# STM32F070x6 register map
File version: 1.0
Registers are 32-bit, read-write, reset 0x0 unless marked. A register's access mark holds for its fields unless they carry their own. Offsets are from the block's base; [hi:lo] are bit positions; {n}, {i} and the like mark numbered series.

## ADC
Base 0x40012708
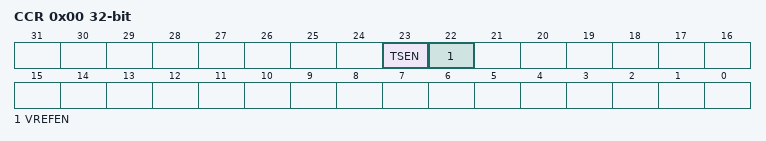
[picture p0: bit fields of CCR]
0x00 CCR — ADC common configuration register
  [23] TSEN — ADC internal path to temperature sensor enable
  [22] VREFEN — ADC internal path to VrefInt enable

## SPI1 — Serial Peripheral Interface
Base 0x40013000
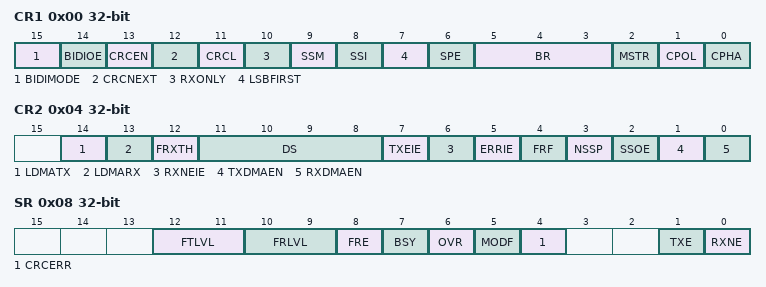
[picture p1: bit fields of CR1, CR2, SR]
0x00 CR1 — SPI Control register 1 (not used in I2S mode)
  [15] BIDIMODE — Bidirectional data mode enable
  [14] BIDIOE — Output enable in bidirectional mode
  [13] CRCEN — Hardware CRC calculation enable
  [12] CRCNEXT — Transmit CRC next
  [11] CRCL — CRC Length
    0=CRC_8BIT (8-bit CRC length); 1=CRC_16BIT (16-bit CRC length)
  [10] RXONLY — Receive only
  [9] SSM — Software slave management
  [8] SSI — Internal slave select
  [7] LSBFIRST — Frame Format
    1=LSB_FIRST (Data is transmitted/received with the LSB first); 0=MSB_FIRST (Data is transmitted/received with the MSB first)
  [6] SPE — SPI Enable
  [5:3] BR — BR[2:0] bits (Baud Rate Control)
    0=DIV2 (BaudRate control equal to fPCLK/2); 1=DIV4 (BaudRate control equal to fPCLK/4); 2=DIV8 (BaudRate control equal to fPCLK/8); 3=DIV16 (BaudRate control equal to fPCLK/16); 4=DIV32 (BaudRate control equal to fPCLK/32); 5=DIV64 (BaudRate control equal to fPCLK/64); 6=DIV128 (BaudRate control equal to fPCLK/128); 7=DIV256 (BaudRate control equal to fPCLK/256)
  [2] MSTR — Master Selection
  [1] CPOL — Clock Polarity
    0=LOW (Clock to 0 when idle); 1=HIGH (Clock to 1 when idle)
  [0] CPHA — Clock Phase
    0=PHASE_1EDGE (First clock transition is the first data capture edge); 1=PHASE_2EDGE (Second clock transition is the first data capture edge)
0x04 CR2 — SPI Control register 2
  [14] LDMATX — Last DMA transfer for transmission
  [13] LDMARX — Last DMA transfer for reception
  [12] FRXTH — FIFO reception Threshold
    0=HALF (RXNE event is generated if FIFO level is greater than or equal to 1/2 (16-bit)); 1=QUARTER (RXNE event is generated if FIFO level is greater than or equal to 1/4 (8-bit))
  [11:8] DS — DS[3:0] Data Size
    {v}=DATAWIDTH_{v+1}BIT (Data length for SPI transfer: {v+1} bits) (v=3..15)
  [7] TXEIE — Tx buffer Empty Interrupt Enable
  [6] RXNEIE — RX buffer Not Empty Interrupt Enable
  [5] ERRIE — Error Interrupt Enable
  [4] FRF — Frame Format Enable
    0=MOTOROLA (Motorola mode. Used as default value); 1=TI (TI mode)
  [3] NSSP — NSS pulse management Enable
  [2] SSOE — SS Output Enable
  [1] TXDMAEN — Tx Buffer DMA Enable
  [0] RXDMAEN — Rx Buffer DMA Enable
0x08 SR — SPI Status register
  [12:11] FTLVL — FIFO Transmission Level
    0=EMPTY (FIFO transmission empty); 1=QUARTER_FULL (FIFO transmission 1/4); 2=HALF_FULL (FIFO transmission 1/2); 3=FULL (FIFO transmission full)
  [10:9] FRLVL — FIFO Reception Level
    0=EMPTY (FIFO reception empty); 1=QUARTER_FULL (FIFO reception 1/4); 2=HALF_FULL (FIFO reception 1/2); 3=FULL (FIFO reception full)
  [8] FRE — TI frame format error
  [7] BSY — Busy flag
  [6] OVR — Overrun flag
  [5] MODF — Mode fault
  [4] CRCERR — CRC Error flag
  [1] TXE — Transmit buffer Empty
  [0] RXNE — Receive buffer Not Empty
0x0C DR — SPI data register
  [31:0] DR — Data Register
0x10 CRCPR — SPI CRC polynomial register (not used in I2S mode)
  [31:0] CRCPOLY — CRC polynomial register
0x14 RXCRCR — SPI Rx CRC register (not used in I2S mode)
  [31:0] RXCRC
0x18 TXCRCR — SPI Tx CRC register (not used in I2S mode)
  [31:0] TXCRC
0x1C I2SCFGR — SPI_I2S configuration register
  [11] I2SMOD — Keep for compatibility

## DBGMCU — Debug MCU
Base 0x40015800
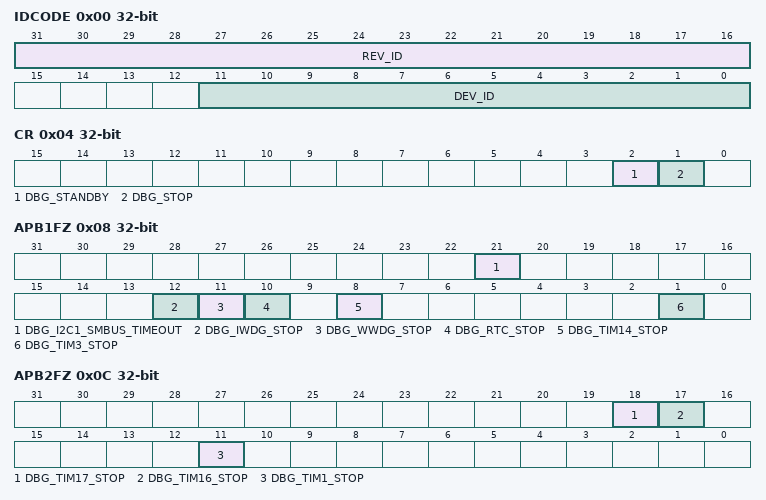
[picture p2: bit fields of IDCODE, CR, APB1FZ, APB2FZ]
0x00 IDCODE — MCU device ID code
  [31:16] REV_ID — REV_ID[15:0] bits (Revision Identifier)
  [11:0] DEV_ID — Device Identifier
0x04 CR — Debug MCU configuration register
  [2] DBG_STANDBY — Debug Standby mode
  [1] DBG_STOP — Debug Stop Mode
0x08 APB1FZ — Debug MCU APB1 freeze register
  [21] DBG_I2C1_SMBUS_TIMEOUT — I2C1 SMBUS timeout mode stopped when Core is halted
  [12] DBG_IWDG_STOP — Debug Independent Watchdog stopped when Core is halted
  [11] DBG_WWDG_STOP — Debug Window Watchdog stopped when Core is halted
  [10] DBG_RTC_STOP — RTC Calendar frozen when core is halted
  [8] DBG_TIM14_STOP — TIM14 counter stopped when core is halted
  [1] DBG_TIM3_STOP — TIM3 counter stopped when core is halted
0x0C APB2FZ — Debug MCU APB2 freeze register
  [18] DBG_TIM17_STOP — TIM17 counter stopped when core is halted
  [17] DBG_TIM16_STOP — TIM16 counter stopped when core is halted
  [11] DBG_TIM1_STOP — TIM1 counter stopped when core is halted
